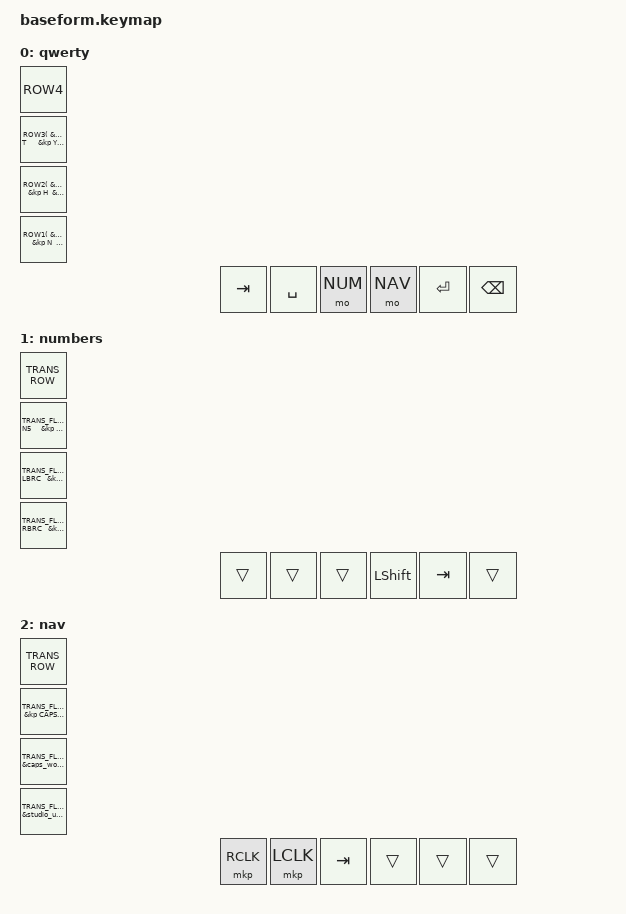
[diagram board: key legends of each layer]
#include <behaviors.dtsi>
#include <dt-bindings/zmk/keys.h>
#include <dt-bindings/zmk/mouse.h>
#include "../keymap_edges.dtsi"

#define ZMK_MOUSE_DEFAULT_MOVE_VAL 5000


#define NUM 1
#define NAV 2

/ {
    behaviors {
        ht: hold_tap {
            compatible = "zmk,behavior-hold-tap";
            label = "HOME_ROW_MOD";
            #binding-cells = <2>;
            flavor = "tap-preferred";
            tapping-term-ms = <220>;
            quick-tap-ms = <150>;
            global-quick-tap;
            bindings = <&kp>, <&kp>;
        };

        mmv {
            acceleration-exponent = <1>;
            time-to-max-speed-ms = <300>;
            delay-ms = <0>;
        };
    };

    keymap {
        compatible = "zmk,keymap";

        default_layer {
            display-name = "qwerty";
            bindings = <
                ROW4
                ROW3( &kp Q       &kp W       &kp E        &kp R       &kp T      &kp Y  &kp U        &kp I        &kp O       &kp P )
                ROW2( &ht LGUI A  &ht LALT S  &ht LCTRL D  &ht LSHFT F  &kp G      &kp H  &ht LSHFT J  &ht RCTRL K  &ht RALT L  &ht LGUI SEMI )
                ROW1( &kp Z       &kp X       &kp C        &kp V       &kp B      &kp N  &kp M        &kp COMMA    &kp DOT     &kp APOS )
                                                   &kp TAB  &kp SPACE  &mo NUM  &mo NAV  &kp RET  &kp BSPC
            >;
        };

        nums_symbols {
            display-name = "numbers";
            bindings = <
                TRANS_ROW
                TRANS_FLANK( &kp N1     &kp N2     &kp N3     &kp N4     &kp N5     &kp N6     &kp N7     &kp N8     &kp N9     &kp BSPC )
                TRANS_FLANK( &kp TILDE  &kp N0     &kp LPAR   &kp LBKT   &kp LBRC   &kp MINUS  &kp UNDER  &kp BSLH   &kp PIPE   &kp SEMI )
                TRANS_FLANK( &kp GRAVE  &kp QMARK  &kp RPAR   &kp RBKT   &kp RBRC   &kp PLUS   &kp EQUAL  &kp COMMA  &kp DOT    &kp FSLH )
                                                   &trans    &trans     &trans     &kp LSHFT  &kp TAB   &trans
            >;
        };

        nav_layer {
            display-name = "nav";
            bindings = <
                TRANS_ROW
                TRANS_FLANK( &kp ESC        &mmv MOVE_UP     &none            &none      &kp CAPS        &kp HOME  &kp PG_DN  &kp PG_UP  &kp END    &kp BSPC )
                TRANS_FLANK( &mmv MOVE_LEFT &mmv MOVE_DOWN   &mmv MOVE_RIGHT  &none      &caps_word      &kp LEFT  &kp DOWN   &kp UP     &kp RIGHT  &kp C_VOL_UP )
                TRANS_FLANK( &none          &none            &trans           &none      &studio_unlock  &none     &none      &none      &none      &kp C_VOL_DN )
                                                   &mkp RCLK    &mkp LCLK        &kp TAB    &trans  &trans     &trans
            >;
        };
    };
};
